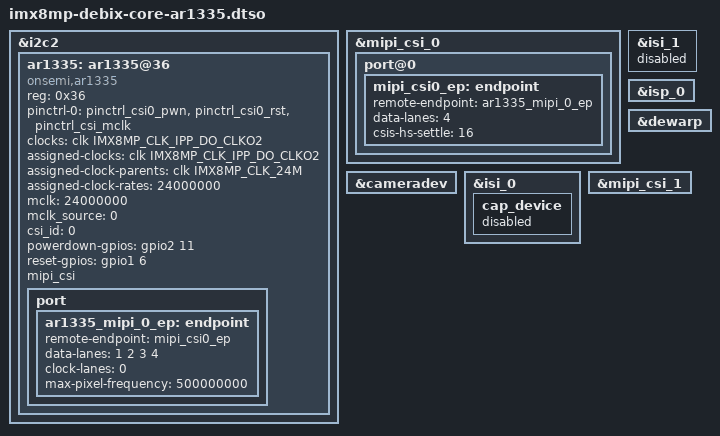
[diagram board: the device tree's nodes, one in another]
// SPDX-License-Identifier: GPL-2.0+
/*
 * Copyright 2020 NXP
 */

//#include "imx8mp-debix-core-board.dts"

///delete-node/ &ov5640_0;

/dts-v1/;
/plugin/;
#include "../../freescale/imx8mp-pinfunc.h"
#include <dt-bindings/clock/imx8mp-clock.h>
#include <dt-bindings/power/imx8mp-power.h>
#include <dt-bindings/reset/imx8mp-reset.h>
#include <dt-bindings/power/imx8mp-power.h>
#include <dt-bindings/gpio/gpio.h>
#include <dt-bindings/input/input.h>
#include <dt-bindings/interrupt-controller/arm-gic.h>
#include <dt-bindings/thermal/thermal.h>


&i2c2 {

	#address-cells = <1>;   // 显式覆盖继承值
    	#size-cells = <0>;      // I2C 设备不需要 size 字段	

	ar1335: ar1335@36 {
		compatible = "onsemi,ar1335";
		reg = <0x36>;
		pinctrl-names = "default";
		pinctrl-0 = <&pinctrl_csi0_pwn>, <&pinctrl_csi0_rst>, <&pinctrl_csi_mclk>;
		clocks = <&clk IMX8MP_CLK_IPP_DO_CLKO2>;
		clock-names = "csi_mclk";
		assigned-clocks = <&clk IMX8MP_CLK_IPP_DO_CLKO2>;
		assigned-clock-parents = <&clk IMX8MP_CLK_24M>;
		assigned-clock-rates = <24000000>;
		mclk = <24000000>;
		mclk_source = <0>;
		
		csi_id = <0>;
		powerdown-gpios = <&gpio2 11 GPIO_ACTIVE_HIGH>;
		reset-gpios = <&gpio1 6 GPIO_ACTIVE_HIGH>;
	
		mipi_csi;
		status = "okay";
		
		port {
			ar1335_mipi_0_ep: endpoint {
				remote-endpoint = <&mipi_csi0_ep>;
				data-lanes = <1 2 3 4>;
				clock-lanes = <0>;
				max-pixel-frequency = /bits/ 64 <500000000>;
			};
		};
	};


};

&mipi_csi_0 { 
	status = "okay";
    
    port@0 {
        mipi_csi0_ep: endpoint {
        ///delete-property/ remote-endpoint;
        remote-endpoint = <&ar1335_mipi_0_ep>;
        data-lanes = <4>;
				csis-hs-settle = <16>;
			};
   };
};

&cameradev {
	status = "okay";
};

&isi_0 {
	cap_device {
		status = "disabled";
	};
};

&isi_1 {
	status = "disabled";
};

&isp_0 {
	status = "okay";
};

&dewarp {
	status = "okay";
};

&mipi_csi_1 {
	/delete-property/ #address-cells;
	/delete-property/ #size-cells;
	/delete-node/port@1;
};


